# ES32F36xx register map
File version: 1.0
Registers are 32-bit, read-write, reset 0x0 unless marked. A register's access mark holds for its fields unless they carry their own. Offsets are from the block's base; lines under a group give offsets from that group; [hi:lo] are bit positions; {n}, {i} and the like mark numbered series; 'fields as' and 'values as' point back to an identical list; <NAME> marks a mode.

## Memory map
0x40000000 AD16C4T0 size 0x2000
0x40000400 AD16C4T1 size 0x2000
0x40000800 GP32C4T0 size 0x2000
0x40000C00 GP32C4T1 size 0x2000
0x40001000 BS16T0 size 0x2000
0x40001400 BS16T1 size 0x2000
0x40001800 GP16C4T0 size 0x2000
0x40001C00 GP16C4T1 size 0x2000
0x40004000 UART0 size 0x2000
0x40004400 UART1 size 0x2000
0x40004800 UART2 size 0x2000
0x40004C00 UART3 size 0x2000
0x40005000 UART4 size 0x2000
0x40005400 UART5 size 0x2000
0x40006000 SPI0 size 0x2000
0x40006400 SPI1 size 0x2000
0x40006800 SPI2 size 0x2000
0x40008000 I2C0 size 0x2000
0x40008400 I2C1 size 0x2000
0x4000B000 CAN0 size 0x2000
0x4000C000 DMA size 0x2000
0x4000D400 QSPI size 0x2000
0x40042000 ADC0 size 0x2000
0x40042400 ADC1 size 0x2000
0x40043000 ACMP0 size 0x2000
0x40043400 ACMP1 size 0x2000
0x40043800 ACMP2 size 0x2000
0x40045000 DAC0 size 0x2000
0x40046000 WWDT size 0x2000
0x40046400 IWDT size 0x2000
0x40048000 BKPC size 0x2000
0x40048400 RTC size 0x2000
0x40048800 TSENSE size 0x2000
0x4004A000 DBGC size 0x2000
0x40080000 SYSCFG size 0x2000
0x40080400 CMU size 0x2000
0x40080800 RMU size 0x2000
0x40080C00 PMU size 0x2000
0x40081000 MSC size 0x2000
0x40084000 GPIOA size 0x2000
0x40084040 GPIOB size 0x2000
0x40084080 GPIOC size 0x2000
0x400840C0 GPIOD size 0x2000
0x40084100 GPIOE size 0x2000
0x40084140 GPIOF size 0x2000
0x40084180 GPIOG size 0x2000
0x400841C0 GPIOH size 0x2000
0x40085000 CRC size 0x2000
0x40085400 CALC size 0x2000
0x40085800 CRYPT size 0x2000
0x40085C00 TRNG size 0x2000
0x40086000 PIS size 0x2000
0x40086400 USB size 0x2000 — Universal Serial Bus
0xA0000000 EBI size 0x2000

## CMU
Base 0x40080400
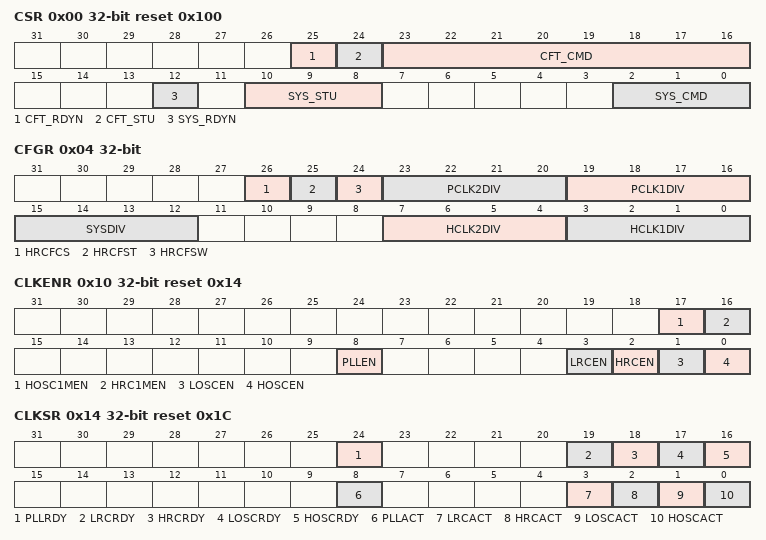
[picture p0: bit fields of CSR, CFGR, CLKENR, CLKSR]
0x00 CSR write reset 0x100
  [25] CFT_RDYN read, [24] CFT_STU read, [23:16] CFT_CMD, [12] SYS_RDYN read, [10:8] SYS_STU read, [2:0] SYS_CMD
0x04 CFGR
  [26] HRCFCS, [25] HRCFST read, [24] HRCFSW, [23:20] PCLK2DIV, [19:16] PCLK1DIV, [15:12] SYSDIV, [7:4] HCLK2DIV, [3:0] HCLK1DIV
0x10 CLKENR reset 0x14
  [17] HOSC1MEN, [16] HRC1MEN, [8] PLLEN, [3] LRCEN, [2] HRCEN, [1] LOSCEN, [0] HOSCEN
0x14 CLKSR read reset 0x1C
  [24] PLLRDY, [19] LRCRDY, [18] HRCRDY, [17] LOSCRDY, [16] HOSCRDY, [8] PLLACT, [3] LRCACT, [2] HRCACT, [1] LOSCACT, [0] HOSCACT
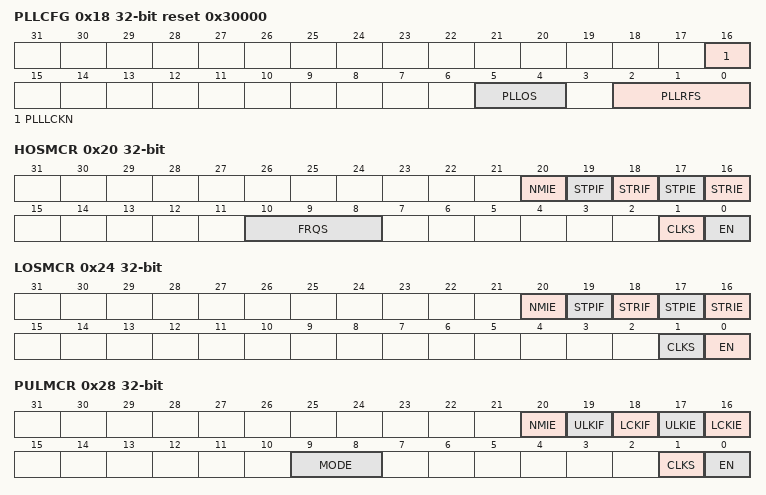
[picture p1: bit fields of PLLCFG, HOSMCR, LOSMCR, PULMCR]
0x18 PLLCFG reset 0x30000
  [16] PLLLCKN read, [5:4] PLLOS, [2:0] PLLRFS
0x1C HOSCCFG reset 0x17
  [4:0] FREQ
0x20 HOSMCR
  [20] NMIE, [19] STPIF, [18] STRIF, [17] STPIE, [16] STRIE, [10:8] FRQS, [1] CLKS read, [0] EN
0x24 LOSMCR read
  [20] NMIE rw, [19] STPIF rw, [18] STRIF rw, [17] STPIE rw, [16] STRIE rw, [1] CLKS, [0] EN
0x28 PULMCR
  [20] NMIE, [19] ULKIF, [18] LCKIF, [17] ULKIE, [16] LCKIE, [9:8] MODE, [1] CLKS read, [0] EN
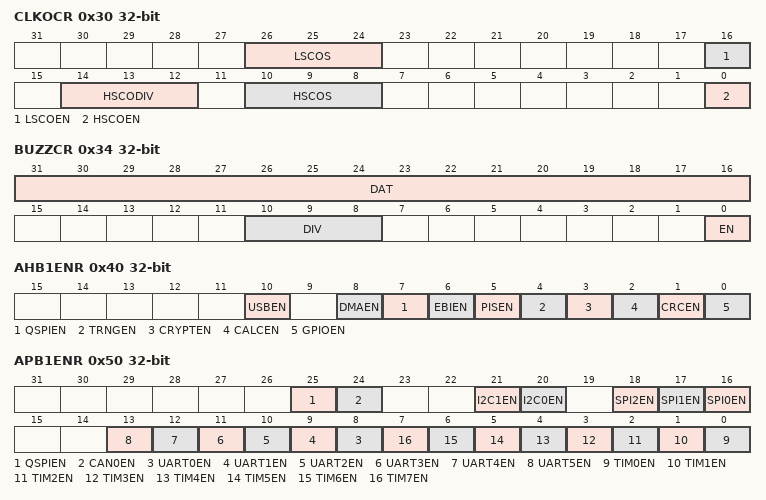
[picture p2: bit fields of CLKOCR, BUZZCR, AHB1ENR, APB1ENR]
0x30 CLKOCR
  [26:24] LSCOS, [16] LSCOEN, [14:12] HSCODIV, [10:8] HSCOS, [0] HSCOEN
0x34 BUZZCR
  [31:16] DAT, [10:8] DIV, [0] EN
0x40 AHB1ENR
  [10] USBEN, [8] DMAEN, [7] QSPIEN, [6] EBIEN, [5] PISEN, [4] TRNGEN, [3] CRYPTEN, [2] CALCEN, [1] CRCEN, [0] GPIOEN
0x50 APB1ENR
  [25] QSPIEN, [24] CAN0EN, [21] I2C1EN, [20] I2C0EN, [18] SPI2EN, [17] SPI1EN, [16] SPI0EN, [n+8] UART{n}EN (n=0..5), [n] TIM{n}EN (n=0..7)
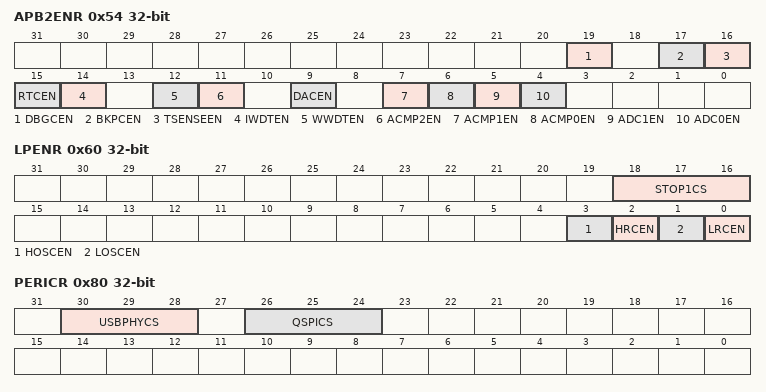
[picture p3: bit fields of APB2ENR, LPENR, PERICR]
0x54 APB2ENR
  [19] DBGCEN, [17] BKPCEN, [16] TSENSEEN, [15] RTCEN, [14] IWDTEN, [12] WWDTEN, [11] ACMP2EN, [9] DACEN, [7] ACMP1EN, [6] ACMP0EN, [5] ADC1EN, [4] ADC0EN
0x60 LPENR
  [18:16] STOP1CS, [3] HOSCEN, [2] HRCEN, [1] LOSCEN, [0] LRCEN
0x80 PERICR
  [30:28] USBPHYCS, [26:24] QSPICS
0x88 PERIDIVR write reset 0x10000000
  [31:28] USBPHYDIV

## RMU
Base 0x40080800
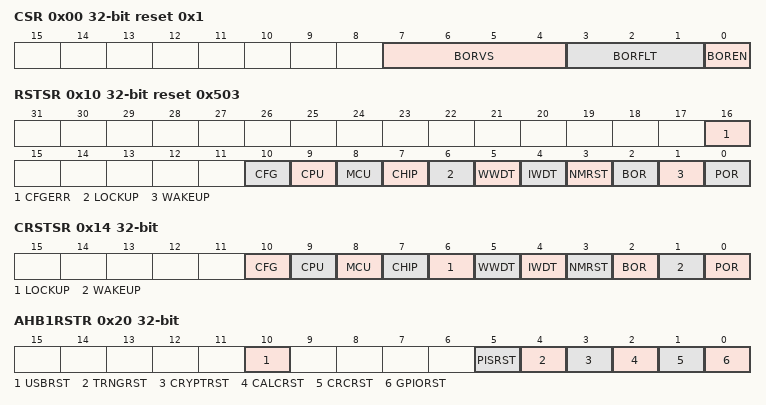
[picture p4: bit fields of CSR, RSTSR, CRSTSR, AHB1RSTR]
0x00 CSR reset 0x1
  [7:4] BORVS, [3:1] BORFLT, [0] BOREN
0x10 RSTSR read reset 0x503
  [16] CFGERR, [10] CFG, [9] CPU, [8] MCU, [7] CHIP, [6] LOCKUP, [5] WWDT, [4] IWDT, [3] NMRST, [2] BOR, [1] WAKEUP, [0] POR
0x14 CRSTSR write
  [10] CFG, [9] CPU, [8] MCU, [7] CHIP, [6] LOCKUP, [5] WWDT, [4] IWDT, [3] NMRST, [2] BOR, [1] WAKEUP, [0] POR
0x20 AHB1RSTR write
  [10] USBRST, [5] PISRST, [4] TRNGRST, [3] CRYPTRST, [2] CALCRST, [1] CRCRST, [0] GPIORST
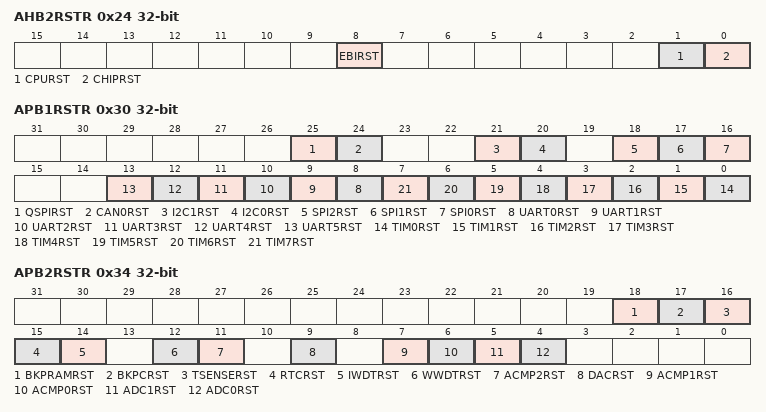
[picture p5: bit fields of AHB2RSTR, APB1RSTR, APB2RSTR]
0x24 AHB2RSTR write
  [8] EBIRST, [1] CPURST, [0] CHIPRST
0x30 APB1RSTR write
  [25] QSPIRST, [24] CAN0RST, [21] I2C1RST, [20] I2C0RST, [18] SPI2RST, [17] SPI1RST, [16] SPI0RST, [n+8] UART{n}RST (n=0..5), [n] TIM{n}RST (n=0..7)
0x34 APB2RSTR write1
  [18] BKPRAMRST, [17] BKPCRST, [16] TSENSERST, [15] RTCRST, [14] IWDTRST, [12] WWDTRST, [11] ACMP2RST, [9] DACRST, [7] ACMP1RST, [6] ACMP0RST, [5] ADC1RST, [4] ADC0RST
